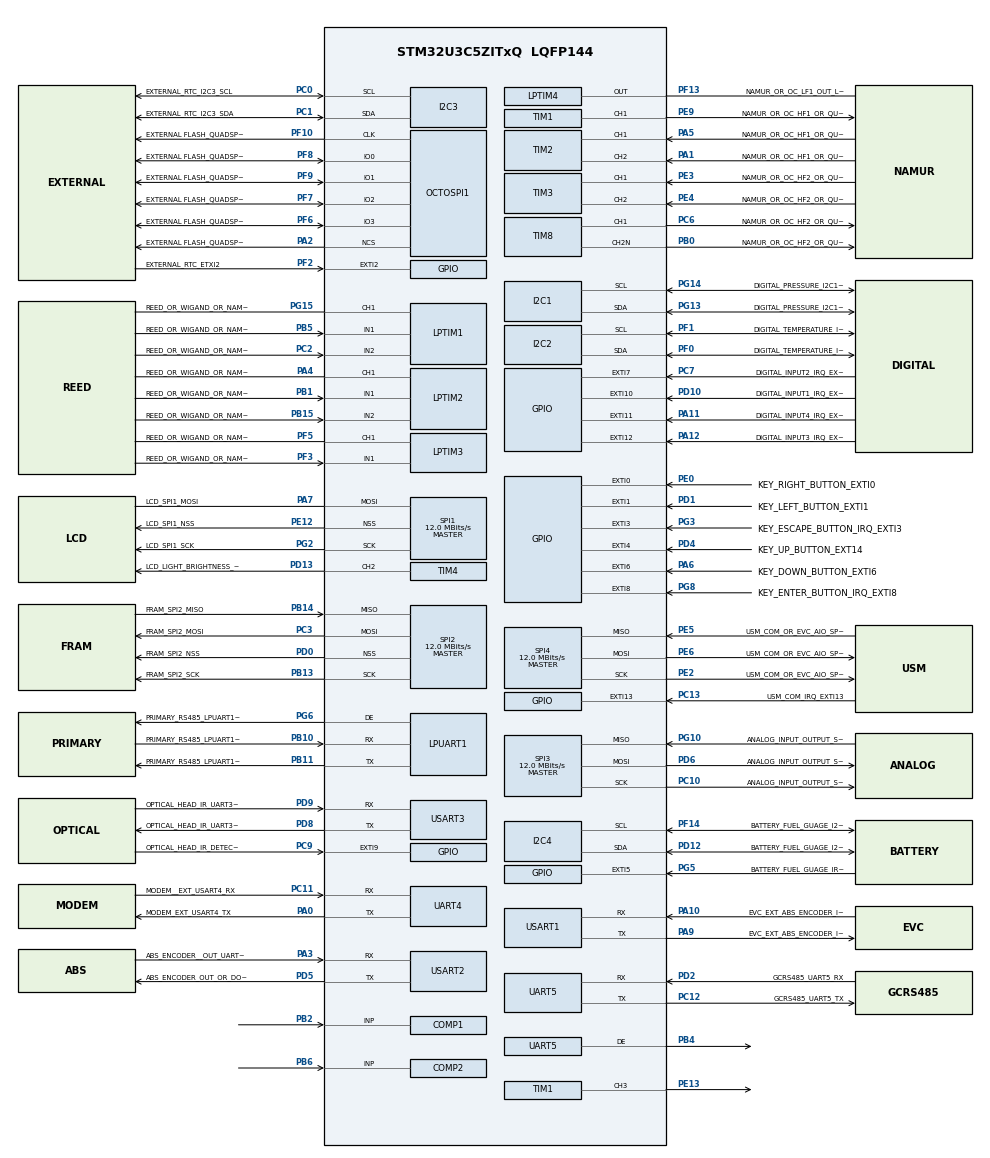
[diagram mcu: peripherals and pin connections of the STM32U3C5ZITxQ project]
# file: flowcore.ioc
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CORTEX_M33_NS.userName=CORTEX_M33
I2C1.Timing=0x00506682
I2C2.Timing=0x00506682
I2C3.Timing=0x00506682
I2C4.Timing=0x00506682
Mcu.Family=STM32U3
Mcu.Name=STM32U3C5ZITxQ
Mcu.Package=LQFP144
NVIC.PriorityGroup=NVIC_PRIORITYGROUP_4
OCTOSPI1.ClockMode=HAL_XSPI_CLOCK_MODE_3
OCTOSPI1.MemorySize=HAL_XSPI_SIZE_32MB
PA0.GPIO_Label=MODEM_EXT_USART4_TX
PA0.Mode=Asynchronous
PA0.Signal=UART4_TX
PA1.GPIO_Label=NAMUR_OR_OC_HF1_OR_QUAD1_S_INPUT_TIM2_CH2
PA1.Signal=S_TIM2_CH2
PA10.GPIO_Label=EVC_EXT_ABS_ENCODER_INPUT_UART1_RX
PA10.Mode=Asynchronous
PA10.Signal=USART1_RX
PA11.GPIO_Label=DIGITAL_INPUT4_IRQ_EXTI11
PA11.Signal=GPXTI11
PA12.GPIO_Label=DIGITAL_INPUT3_IRQ_EXTI12
PA12.Signal=GPXTI12
PA13\ (JTMS/SWDIO).Mode=JTAG_4_pins
PA13\ (JTMS/SWDIO).Signal=DEBUG_JTMS-SWDIO
PA14\ (JTCK/SWCLK).Mode=JTAG_4_pins
PA14\ (JTCK/SWCLK).Signal=DEBUG_JTCK-SWCLK
PA15\ (JTDI).Mode=JTAG_4_pins
PA15\ (JTDI).Signal=DEBUG_JTDI
PA2.GPIO_Label=EXTERNAL FLASH_QUADSPI_BK1_NCS
PA2.Mode=quad_mode
PA2.Signal=OCTOSPI1_NCS
PA3.GPIO_Label=ABS_ENCODER__OUT_UART2_RX
PA3.Mode=Asynchronous
PA3.Signal=USART2_RX
PA4.GPIO_Label=REED_OR_WIGAND_OR_NAMUR_LF3_OR_QUAD2_P_INPUT_LPTIM2_CH1
PA4.Signal=S_LPTIM2_CH1
PA5.GPIO_Label=NAMUR_OR_OC_HF1_OR_QUAD1_P_INPUT_TIM2_CH1
PA5.Signal=S_TIM2_CH1
PA6.GPIO_Label=KEY_DOWN_BUTTON_EXTI6
PA6.Signal=GPXTI6
PA7.GPIO_Label=LCD_SPI1_MOSI 
PA7.Mode=Simplex_Bidirectional_Master
PA7.Signal=SPI1_MOSI
PA9.GPIO_Label=EVC_EXT_ABS_ENCODER_INPUT_UART1_TX
PA9.Mode=Asynchronous
PA9.Signal=USART1_TX
PB0.GPIO_Label=NAMUR_OR_OC_HF2_OR_QUAD2_S_OUTPUT_TIM8_CH1N
PB0.Mode=PWM Generation2 CH2N
PB0.Signal=TIM8_CH2N
PB1.GPIO_Label=REED_OR_WIGAND_OR_NAMUR_LF3_OR_QUAD2_P_INPUT_LPTIM2_IN1
PB1.Mode=Encoder_mode_occur1
PB1.Signal=LPTIM2_IN1
PB10.GPIO_Label=PRIMARY_RS485_LPUART1_RX
PB10.Mode=Asynchronous
PB10.Signal=LPUART1_RX
PB11.GPIO_Label=PRIMARY_RS485_LPUART1_TX
PB11.Mode=Asynchronous
PB11.Signal=LPUART1_TX
PB13.GPIO_Label=FRAM_SPI2_SCK
PB13.Mode=Full_Duplex_Master
PB13.Signal=SPI2_SCK
PB14.GPIO_Label=FRAM_SPI2_MISO
PB14.Mode=Full_Duplex_Master
PB14.Signal=SPI2_MISO
PB15.GPIO_Label=REED_OR_WIGAND_OR_NAMUR_LF3_OR_QUAD2_S_INPUT_LPTIM2_IN2
PB15.Mode=Encoder_mode_occur1
PB15.Signal=LPTIM2_IN2
PB2.Mode=INP
PB2.Signal=COMP1_INP
PB3\ (JTDO/TRACESWO).Mode=JTAG_4_pins
PB3\ (JTDO/TRACESWO).Signal=DEBUG_JTDO-SWO
PB4\ (NJTRST).Mode=Hardware Flow Control (RS485)
PB4\ (NJTRST).Signal=UART5_DE
PB5.GPIO_Label=REED_OR_WIGAND_OR_NAMUR_LF1_OR_QUAD1_P_INPUT_LPTIM1_IN1
PB5.Mode=Encoder_mode_occur1
PB5.Signal=LPTIM1_IN1
PB6.Mode=INP
PB6.Signal=COMP2_INP
PC0.GPIO_Label=EXTERNAL_RTC_I2C3_SCL
PC0.Mode=I2C
PC0.Signal=I2C3_SCL
PC1.GPIO_Label=EXTERNAL_RTC_I2C3_SDA
PC1.Mode=I2C
PC1.Signal=I2C3_SDA
PC10.GPIO_Label=ANALOG_INPUT_OUTPUT_SPI3_SCK
PC10.Mode=Full_Duplex_Master
PC10.Signal=SPI3_SCK
PC11.GPIO_Label=MODEM__EXT_USART4_RX
PC11.Mode=Asynchronous
PC11.Signal=UART4_RX
PC12.GPIO_Label=GCRS485_UART5_TX
PC12.Mode=Asynchronous
PC12.Signal=UART5_TX
PC13.GPIO_Label=USM_COM_IRQ_EXTI13
PC13.Signal=GPXTI13
PC14-OSC32_IN\ (PC14).GPIO_Label=RCC_OSCC32_IN
PC14-OSC32_IN\ (PC14).Mode=LSE-External-Oscillator
PC14-OSC32_IN\ (PC14).Signal=RCC_OSC32_IN
PC15-OSC32_OUT\ (PC15).GPIO_Label=RCC_OSCC32_OUT
PC15-OSC32_OUT\ (PC15).Mode=LSE-External-Oscillator
PC15-OSC32_OUT\ (PC15).Signal=RCC_OSC32_OUT
PC2.GPIO_Label=REED_OR_WIGAND_OR_NAMUR_LF2_OR_QUAD1_S_INPUT_LPTIM1_IN2
PC2.Mode=Encoder_mode_occur1
PC2.Signal=LPTIM1_IN2
PC3.GPIO_Label=FRAM_SPI2_MOSI
PC3.Mode=Full_Duplex_Master
PC3.Signal=SPI2_MOSI
PC6.GPIO_Label=NAMUR_OR_OC_HF2_OR_QUAD2_P_OUTPUT_OR_DO2_TIM8_CH1
PC6.Signal=S_TIM8_CH1
PC7.GPIO_Label=DIGITAL_INPUT2_IRQ_EXTI7
PC7.Signal=GPXTI7
PC9.GPIO_Label=OPTICAL_HEAD_IR_DETECT_IRQ_EXTI9
PC9.Signal=GPXTI9
PD0.GPIO_Label=FRAM_SPI2_NSS
PD0.Mode=NSS_Signal_Hard_Output
PD0.Signal=SPI2_NSS
PD1.GPIO_Label=KEY_LEFT_BUTTON_EXTI1
PD1.Signal=GPXTI1
PD10.GPIO_Label=DIGITAL_INPUT1_IRQ_EXTI10
PD10.Signal=GPXTI10
PD12.GPIO_Label=BATTERY_FUEL_GUAGE_I2C4_SDA
PD12.Mode=I2C
PD12.Signal=I2C4_SDA
PD13.GPIO_Label=LCD_LIGHT_BRIGHTNESS_CONTROLL_PWM_TIM4_CH2
PD13.Signal=S_TIM4_CH2
PD2.GPIO_Label=GCRS485_UART5_RX
PD2.Mode=Asynchronous
PD2.Signal=UART5_RX
PD4.GPIO_Label=KEY_UP_BUTTON_EXT14
PD4.Signal=GPXTI4
PD5.GPIO_Label=ABS_ENCODER_OUT_OR_DO3_UART2_TX
PD5.Mode=Asynchronous
PD5.Signal=USART2_TX
PD6.GPIO_Label=ANALOG_INPUT_OUTPUT_SPI3_MOSI
PD6.Mode=Full_Duplex_Master
PD6.Signal=SPI3_MOSI
PD8.GPIO_Label=OPTICAL_HEAD_IR_UART3_TX
PD8.Mode=Asynchronous
PD8.Signal=USART3_TX
PD9.GPIO_Label=OPTICAL_HEAD_IR_UART3_RX_OR_IRQ_EXTI9
PD9.Mode=Asynchronous
PD9.Signal=USART3_RX
PE0.GPIO_Label=KEY_RIGHT_BUTTON_EXTI0
PE0.Signal=GPXTI0
PE12.GPIO_Label=LCD_SPI1_NSS
PE12.Mode=NSS_Signal_Hard_Output
PE12.Signal=SPI1_NSS
PE13.Signal=S_TIM1_CH3
PE2.GPIO_Label=USM_COM_OR_EVC_AIO_SPI4_SCK
PE2.Mode=Full_Duplex_Master
PE2.Signal=SPI4_SCK
PE3.GPIO_Label=NAMUR_OR_OC_HF2_OR_QUAD2_P_INPUT_TIM3_CH1
PE3.Signal=S_TIM3_CH1
PE4.GPIO_Label=NAMUR_OR_OC_HF2_OR_QUAD2_S_INPUT_TIM3_CH2
PE4.Signal=S_TIM3_CH2
PE5.GPIO_Label=USM_COM_OR_EVC_AIO_SPI4_MISO
PE5.Mode=Full_Duplex_Master
PE5.Signal=SPI4_MISO
PE6.GPIO_Label=USM_COM_OR_EVC_AIO_SPI4_MOSI
PE6.Mode=Full_Duplex_Master
PE6.Signal=SPI4_MOSI
PE9.GPIO_Label=NAMUR_OR_OC_HF1_OR_QUAD1_P_OUTPUT_OR_DO1_TIM1_CH1
PE9.Signal=S_TIM1_CH1
PF0.GPIO_Label=DIGITAL_TEMPERATURE_I2C2_SDA
PF0.Mode=I2C
PF0.Signal=I2C2_SDA
PF1.GPIO_Label=DIGITAL_TEMPERATURE_I2C2_SCL
PF1.Mode=I2C
PF1.Signal=I2C2_SCL
PF10.GPIO_Label=EXTERNAL FLASH_QUADSPI_CLK
PF10.Mode=quad_mode
PF10.Signal=OCTOSPI1_CLK
PF13.GPIO_Label=NAMUR_OR_OC_LF1_OUT_LPTIM4_OUT
PF13.Mode=WaveformGeneration
PF13.Signal=LPTIM4_OUT
PF14.GPIO_Label=BATTERY_FUEL_GUAGE_I2C4_SCL
PF14.Mode=I2C
PF14.Signal=I2C4_SCL
PF2.GPIO_Label=EXTERNAL_RTC_ETXI2
PF2.Signal=GPXTI2
PF3.GPIO_Label=REED_OR_WIGAND_OR_NAMUR_LF2_OR_QUAD1_S_INPUT_LPTIM3_IN1
PF3.Mode=Counts_external_clock_with_synchro_01_occur1
PF3.Signal=LPTIM3_IN1
PF5.GPIO_Label=REED_OR_WIGAND_OR_NAMUR_LF2_OR_QUAD1_S_INPUT_LPTIM3_CH1
PF5.Signal=S_LPTIM3_CH1
PF6.GPIO_Label=EXTERNAL FLASH_QUADSPI_BK1_IO3
PF6.Mode=OCTOSPI1_IO[3\:0]
PF6.Signal=OCTOSPI1_IO3
PF7.GPIO_Label=EXTERNAL FLASH_QUADSPI_BK1_IO2
PF7.Mode=OCTOSPI1_IO[3\:0]
PF7.Signal=OCTOSPI1_IO2
PF8.GPIO_Label=EXTERNAL FLASH_QUADSPI_BK1_IO0
PF8.Mode=OCTOSPI1_IO[3\:0]
PF8.Signal=OCTOSPI1_IO0
PF9.GPIO_Label=EXTERNAL FLASH_QUADSPI_BK1_IO1
PF9.Mode=OCTOSPI1_IO[3\:0]
PF9.Signal=OCTOSPI1_IO1
PG10.GPIO_Label=ANALOG_INPUT_OUTPUT_SPI3_MISO
PG10.Mode=Full_Duplex_Master
PG10.Signal=SPI3_MISO
PG13.GPIO_Label=DIGITAL_PRESSURE_I2C1_SDA
PG13.Mode=I2C
PG13.Signal=I2C1_SDA
PG14.GPIO_Label=DIGITAL_PRESSURE_I2C1_SCL
PG14.Mode=I2C
PG14.Signal=I2C1_SCL
PG15.GPIO_Label=REED_OR_WIGAND_OR_NAMUR_LF1_OR_QUAD1_P_INPUT_LPTIM1_CH1
PG15.Signal=S_LPTIM1_CH1
PG2.GPIO_Label=LCD_SPI1_SCK
PG2.Mode=Simplex_Bidirectional_Master
PG2.Signal=SPI1_SCK
PG3.GPIO_Label=KEY_ESCAPE_BUTTON_IRQ_EXTI3
PG3.Signal=GPXTI3
PG5.GPIO_Label=BATTERY_FUEL_GUAGE_IRQ_ETXI15
PG5.Signal=GPXTI5
PG6.GPIO_Label=PRIMARY_RS485_LPUART1_DE
PG6.Mode=Hardware Flow Control (RS485)
PG6.Signal=LPUART1_DE
PG8.GPIO_Label=KEY_ENTER_BUTTON_IRQ_EXTI8
PG8.Signal=GPXTI8
PH0-OSC_IN\ (PH0).Mode=HSE-External-Oscillator
PH0-OSC_IN\ (PH0).Signal=RCC_OSC_IN
PH1-OSC_OUT\ (PH1).Mode=HSE-External-Oscillator
PH1-OSC_OUT\ (PH1).Signal=RCC_OSC_OUT
ProjectManager.HeapSize=0x200
ProjectManager.StackSize=0x400
ProjectManager.TargetToolchain=STM32CubeIDE
RCC.ADCFreq_Value=24000000
RCC.AHBFreq_Value=24000000
RCC.APB1Freq_Value=24000000
RCC.APB1TimFreq_Value=24000000
RCC.APB2Freq_Value=24000000
RCC.APB2TimFreq_Value=24000000
RCC.APB3Freq_Value=24000000
RCC.CortexFreq_Value=3000000
RCC.HCLKFreq_Value=24000000
RCC.HSE_VALUE=16000000
RCC.HSI48_VALUE=48000000
RCC.HSI_VALUE=16000000
RCC.LPTIM1CLockSelection=RCC_LPTIM1CLKSOURCE_LSE
RCC.LPTIM2CLockSelection=RCC_LPTIM2CLKSOURCE_LSE
RCC.LPTIM3CLockSelection=RCC_LPTIM34CLKSOURCE_LSE
RCC.LSIDIV_VALUE=32000
RCC.MSIKSource=RCC_MSI_RC1
RCC.MSISDIV=RCC_MSI_DIV1
RCC.MSISSource=RCC_MSI_RC1
RCC.RTCClockSelection=RCC_RTCCLKSOURCE_LSE
RCC.SYSCLKFreq_VALUE=24000000
RCC.USBFreq_Value=24000000
SH.S_LPTIM1_CH1.0=LPTIM1_CH1,InputIO_CH1
SH.S_LPTIM2_CH1.0=LPTIM2_CH1,InputIO_CH1
SH.S_LPTIM3_CH1.0=LPTIM3_CH1,InputIO_CH1
SH.S_TIM1_CH1.0=TIM1_CH1,PWM Generation1 CH1
SH.S_TIM1_CH3.0=TIM1_CH3,PWM Generation3 CH3
SH.S_TIM2_CH1.0=TIM2_CH1,Encoder_Interface
SH.S_TIM2_CH2.0=TIM2_CH2,Encoder_Interface
SH.S_TIM3_CH1.0=TIM3_CH1,Encoder_Interface
SH.S_TIM3_CH2.0=TIM3_CH2,Encoder_Interface
SH.S_TIM4_CH2.0=TIM4_CH2,PWM Generation2 CH2
SH.S_TIM8_CH1.0=TIM8_CH1,PWM Generation1 CH1
SPI1.CalculateBaudRate=12.0 MBits/s
SPI1.DataSize=SPI_DATASIZE_8BIT
SPI1.Direction=SPI_DIRECTION_1LINE
SPI1.Mode=SPI_MODE_MASTER
SPI1.VirtualNSS=VM_NSSHARD
SPI1.VirtualType=VM_MASTER
SPI2.CalculateBaudRate=12.0 MBits/s
SPI2.Direction=SPI_DIRECTION_2LINES
SPI2.Mode=SPI_MODE_MASTER
SPI2.VirtualNSS=VM_NSSHARD
SPI2.VirtualType=VM_MASTER
SPI3.CalculateBaudRate=12.0 MBits/s
SPI3.Direction=SPI_DIRECTION_2LINES
SPI3.Mode=SPI_MODE_MASTER
SPI3.NSSPMode=SPI_NSS_PULSE_ENABLE
SPI3.VirtualType=VM_MASTER
SPI4.CalculateBaudRate=12.0 MBits/s
SPI4.Direction=SPI_DIRECTION_2LINES
SPI4.Mode=SPI_MODE_MASTER
SPI4.VirtualType=VM_MASTER
TIM1.AutoReloadPreload=TIM_AUTORELOAD_PRELOAD_DISABLE
TIM1.Channel-Output\ Compare2\ No\ Output=TIM_CHANNEL_2
TIM1.Channel-Output\ Compare4\ No\ Output=TIM_CHANNEL_4
TIM1.Channel-PWM\ Generation1\ CH1=TIM_CHANNEL_1
TIM1.Channel-PWM\ Generation3\ CH3=TIM_CHANNEL_3
TIM1.CounterMode=TIM_COUNTERMODE_CENTERALIGNED3
TIM1.OC1Preload_PWM=DISABLE
TIM1.OC3Preload_PWM=DISABLE
TIM1.OCMode_PWM-PWM\ Generation1\ CH1=TIM_OCMODE_ASSYMETRIC_PWM1
TIM1.OCMode_PWM-PWM\ Generation3\ CH3=TIM_OCMODE_ASSYMETRIC_PWM2
TIM1.PeriodNoDither=500
TIM1.Prescaler=23
TIM1.PulseNoDither_1=125
TIM1.PulseNoDither_2=375
TIM1.PulseNoDither_3=375
TIM1.PulseNoDither_4=25
TIM1.RepetitionCounter=1999
TIM4.Channel-PWM\ Generation2\ CH2=TIM_CHANNEL_2
TIM8.Channel-PWM\ Generation1\ CH1=TIM_CHANNEL_1
TIM8.Channel-PWM\ Generation2\ CH2N=TIM_CHANNEL_2
USART1.VirtualMode-Asynchronous=VM_ASYNC
USART2.VirtualMode-Asynchronous=VM_ASYNC
USART3.VirtualMode-Asynchronous=VM_ASYNC
VP_COMP1_VS_VREFINT.Mode=VREFINT
VP_COMP2_VS_VREFINT.Mode=VREFINT
VP_CORTEX_M33_NS_VS_Hclk.Mode=Hclk_Mode
VP_ICACHE_VS_ICACHE.Mode=DirectMappedCache
VP_LPTIM1_VS_CH1.Mode=Channel_1_Active
VP_LPTIM2_VS_CH1.Mode=Channel_1_Active
VP_LPTIM3_VS_CH1.Mode=Channel_1_Active
VP_LPTIM4_VS_LPTIM_counterModeInternalClock.Mode=Counts__internal_clock_event_00
VP_PWR_VS_DBSignals.Mode=DisableDeadBatterySignals
VP_PWR_VS_SECSignals.Mode=Security/Privilege
VP_RTC_VS_RTC_Activate.Mode=RTC_Enabled
VP_TIM1_VS_ClockSourceINT.Mode=Internal
VP_TIM1_VS_no_output2.Mode=Output Compare2 No Output
VP_TIM1_VS_no_output4.Mode=Output Compare4 No Output
board=custom

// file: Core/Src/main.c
/* USER CODE BEGIN Header */
/**
  ******************************************************************************
  * @file           : main.c
  * @brief          : Main program body
  ******************************************************************************
  * @attention
  *
  * Copyright (c) 2026 STMicroelectronics.
  * All rights reserved.
  *
  * This software is licensed under terms that can be found in the LICENSE file
  * in the root directory of this software component.
  * If no LICENSE file comes with this software, it is provided AS-IS.
  *
  ******************************************************************************
  */
/* USER CODE END Header */
#include "main.h"

COMP_HandleTypeDef hcomp1;
COMP_HandleTypeDef hcomp2;

I2C_HandleTypeDef hi2c1;
I2C_HandleTypeDef hi2c2;
I2C_HandleTypeDef hi2c3;
I2C_HandleTypeDef hi2c4;

LPTIM_HandleTypeDef hlptim1;
LPTIM_HandleTypeDef hlptim2;
LPTIM_HandleTypeDef hlptim3;
LPTIM_HandleTypeDef hlptim4;

UART_HandleTypeDef hlpuart1;
UART_HandleTypeDef huart4;
UART_HandleTypeDef huart5;
UART_HandleTypeDef huart1;
UART_HandleTypeDef huart2;
UART_HandleTypeDef huart3;

XSPI_HandleTypeDef hxspi1;

RTC_HandleTypeDef hrtc;

SPI_HandleTypeDef hspi1;
SPI_HandleTypeDef hspi2;
SPI_HandleTypeDef hspi3;
SPI_HandleTypeDef hspi4;

TIM_HandleTypeDef htim1;
TIM_HandleTypeDef htim2;
TIM_HandleTypeDef htim3;
TIM_HandleTypeDef htim4;
TIM_HandleTypeDef htim8;

void SystemClock_Config(void);
static void MX_GPIO_Init(void);
static void MX_I2C1_Init(void);
static void MX_I2C2_Init(void);
static void MX_I2C3_Init(void);
static void MX_LPUART1_UART_Init(void);
static void MX_UART4_Init(void);
static void MX_UART5_Init(void);
static void MX_USART1_UART_Init(void);
static void MX_USART2_UART_Init(void);
static void MX_USART3_UART_Init(void);
static void MX_OCTOSPI1_Init(void);
static void MX_SPI1_Init(void);
static void MX_SPI2_Init(void);
static void MX_SPI3_Init(void);
static void MX_SPI4_Init(void);
static void MX_LPTIM1_Init(void);
static void MX_LPTIM3_Init(void);
static void MX_I2C4_Init(void);
static void MX_ICACHE_Init(void);
static void MX_RTC_Init(void);
static void MX_COMP1_Init(void);
static void MX_COMP2_Init(void);
static void MX_LPTIM2_Init(void);
static void MX_LPTIM4_Init(void);
static void MX_TIM1_Init(void);
static void MX_TIM2_Init(void);
static void MX_TIM3_Init(void);
static void MX_TIM8_Init(void);
static void MX_TIM4_Init(void);

int main(void)
{

  /* MCU Configuration--------------------------------------------------------*/

  /* Reset of all peripherals, Initializes the Flash interface and the Systick. */
  HAL_Init();

  /* Configure the system clock */
  SystemClock_Config();

  /* Initialize all configured peripherals */
  MX_GPIO_Init();
  MX_I2C1_Init();
  MX_I2C2_Init();
  MX_I2C3_Init();
  MX_LPUART1_UART_Init();
  MX_UART4_Init();
  MX_UART5_Init();
  MX_USART1_UART_Init();
  MX_USART2_UART_Init();
  MX_USART3_UART_Init();
  MX_OCTOSPI1_Init();
  MX_SPI1_Init();
  MX_SPI2_Init();
  MX_SPI3_Init();
  MX_SPI4_Init();
  MX_LPTIM1_Init();
  MX_LPTIM3_Init();
  MX_I2C4_Init();
  MX_ICACHE_Init();
  MX_RTC_Init();
  MX_COMP1_Init();
  MX_COMP2_Init();
  MX_LPTIM2_Init();
  MX_LPTIM4_Init();
  MX_TIM1_Init();
  MX_TIM2_Init();
  MX_TIM3_Init();
  MX_TIM8_Init();
  MX_TIM4_Init();
  /* USER CODE BEGIN 2 */

  TIM_OC_InitTypeDef phaseConfig = {0};

  const uint32_t channels[4] = {
      TIM_CHANNEL_1, TIM_CHANNEL_2,
      TIM_CHANNEL_3, TIM_CHANNEL_4
  };

  const uint32_t compareValues[4] = {
      125, 375, 375, 125
  };

  phaseConfig.OCMode = TIM_OCMODE_ASYMMETRIC_PWM2;
  phaseConfig.OCPolarity = TIM_OCPOLARITY_HIGH;
  phaseConfig.OCNPolarity = TIM_OCNPOLARITY_HIGH;
  phaseConfig.OCFastMode = TIM_OCFAST_DISABLE;
  phaseConfig.OCIdleState = TIM_OCIDLESTATE_RESET;
  phaseConfig.OCNIdleState = TIM_OCNIDLESTATE_RESET;

  for (uint32_t i = 0; i < 4; i++)
  {
      phaseConfig.Pulse = compareValues[i];

      if (HAL_TIM_PWM_ConfigChannel(
              &htim1, &phaseConfig, channels[i]) != HAL_OK)
      {
          Error_Handler();
      }
  }

  /* Stop after 1000 complete up/down periods. */
  SET_BIT(htim1.Instance->CR1, TIM_CR1_OPM);

  /* Load all timing values before starting. */
  htim1.Instance->EGR = TIM_EGR_UG;
  __HAL_TIM_CLEAR_FLAG(&htim1, TIM_FLAG_UPDATE);

  /* Enable A and B together, then start their shared counter. */
  SET_BIT(htim1.Instance->CCER,
          TIM_CCER_CC1E | TIM_CCER_CC3E);

  __HAL_TIM_MOE_ENABLE(&htim1);
  __HAL_TIM_ENABLE(&htim1);

  //////////////////////////////////////////////////////////

  // SET_BIT(htim1.Instance->CR1, TIM_CR1_OPM);

  // htim1.Instance->EGR = TIM_EGR_UG;
  // __HAL_TIM_CLEAR_FLAG(&htim1, TIM_FLAG_UPDATE);

  // if (HAL_TIM_PWM_Start(&htim1, TIM_CHANNEL_1) != HAL_OK)
  // {
  //     Error_Handler();
  // }
  /* USER CODE END 2 */

  /* Infinite loop */
  while (1)
  {

    /* USER CODE BEGIN 3 */
    while ((htim1.Instance->CR1 & TIM_CR1_CEN) != 0U)
    {
    }

    /* Keep the output LOW for 10 seconds. */
    HAL_Delay(10000);

    /* Reload the counter for the next 500-pulse burst. */
    htim1.Instance->EGR = TIM_EGR_UG;
    __HAL_TIM_CLEAR_FLAG(&htim1, TIM_FLAG_UPDATE);

    /* Restart the counter; the PWM channel remains enabled. */
    __HAL_TIM_ENABLE(&htim1);
  }

  /* USER CODE END 3 */
}

void SystemClock_Config(void)
{
  RCC_OscInitTypeDef RCC_OscInitStruct = {0};
  RCC_ClkInitTypeDef RCC_ClkInitStruct = {0};

  /** Configure the System Power Supply
  */
  if (HAL_PWREx_ConfigSupply(PWR_SMPS_SUPPLY) != HAL_OK)
  {
    Error_Handler();
  }

  /** Configure the main internal regulator output voltage
  */
  if (HAL_PWREx_ControlVoltageScaling(PWR_REGULATOR_VOLTAGE_SCALE2) != HAL_OK)
  {
    Error_Handler();
  }

  /** Configure LSE Drive Capability
  */
  HAL_PWR_EnableBkUpAccess();
  __HAL_RCC_LSEDRIVE_CONFIG(RCC_LSEDRIVE_LOW);

  /** Initializes the CPU, AHB and APB buses clocks
  */
  RCC_OscInitStruct.OscillatorType = RCC_OSCILLATORTYPE_LSE|RCC_OSCILLATORTYPE_MSIS;
  RCC_OscInitStruct.LSEState = RCC_LSE_ON;
  RCC_OscInitStruct.MSISState = RCC_MSI_ON;
  RCC_OscInitStruct.MSISSource = RCC_MSI_RC1;
  RCC_OscInitStruct.MSISDiv = RCC_MSI_DIV1;
  if (HAL_RCC_OscConfig(&RCC_OscInitStruct) != HAL_OK)
  {
    Error_Handler();
  }

  /** Initializes the CPU, AHB and APB buses clocks
  */
  RCC_ClkInitStruct.ClockType = RCC_CLOCKTYPE_HCLK|RCC_CLOCKTYPE_SYSCLK
                              |RCC_CLOCKTYPE_PCLK1|RCC_CLOCKTYPE_PCLK2
                              |RCC_CLOCKTYPE_PCLK3;
  RCC_ClkInitStruct.SYSCLKSource = RCC_SYSCLKSOURCE_MSIS;
  RCC_ClkInitStruct.AHBCLKDivider = RCC_SYSCLK_DIV1;
  RCC_ClkInitStruct.APB1CLKDivider = RCC_HCLK_DIV1;
  RCC_ClkInitStruct.APB2CLKDivider = RCC_HCLK_DIV1;
  RCC_ClkInitStruct.APB3CLKDivider = RCC_HCLK_DIV1;

  if (HAL_RCC_ClockConfig(&RCC_ClkInitStruct, FLASH_LATENCY_1) != HAL_OK)
  {
    Error_Handler();
  }
}

static void MX_COMP1_Init(void)
{

  hcomp1.Instance = COMP1;
  hcomp1.Init.InputPlus = COMP_INPUT_PLUS_IO2;
  hcomp1.Init.InputMinus = COMP_INPUT_MINUS_VREFINT;
  hcomp1.Init.OutputPol = COMP_OUTPUTPOL_NONINVERTED;
  hcomp1.Init.WindowOutput = COMP_WINDOWOUTPUT_EACH_COMP;
  hcomp1.Init.Hysteresis = COMP_HYSTERESIS_NONE;
  hcomp1.Init.BlankingSrce = COMP_BLANKINGSRC_NONE;
  hcomp1.Init.Mode = COMP_POWERMODE_HIGHSPEED;
  hcomp1.Init.WindowMode = COMP_WINDOWMODE_DISABLE;
  hcomp1.Init.TriggerMode = COMP_TRIGGERMODE_NONE;
  if (HAL_COMP_Init(&hcomp1) != HAL_OK)
  {
    Error_Handler();
  }

}

static void MX_COMP2_Init(void)
{

  hcomp2.Instance = COMP2;
  hcomp2.Init.InputPlus = COMP_INPUT_PLUS_IO2;
  hcomp2.Init.InputMinus = COMP_INPUT_MINUS_VREFINT;
  hcomp2.Init.OutputPol = COMP_OUTPUTPOL_NONINVERTED;
  hcomp2.Init.WindowOutput = COMP_WINDOWOUTPUT_EACH_COMP;
  hcomp2.Init.Hysteresis = COMP_HYSTERESIS_NONE;
  hcomp2.Init.BlankingSrce = COMP_BLANKINGSRC_NONE;
  hcomp2.Init.Mode = COMP_POWERMODE_HIGHSPEED;
  hcomp2.Init.WindowMode = COMP_WINDOWMODE_DISABLE;
  hcomp2.Init.TriggerMode = COMP_TRIGGERMODE_NONE;
  if (HAL_COMP_Init(&hcomp2) != HAL_OK)
  {
    Error_Handler();
  }

}

static void MX_I2C1_Init(void)
{

  hi2c1.Instance = I2C1;
  hi2c1.Init.Timing = 0x00506682;
  hi2c1.Init.OwnAddress1 = 0;
  hi2c1.Init.AddressingMode = I2C_ADDRESSINGMODE_7BIT;
  hi2c1.Init.DualAddressMode = I2C_DUALADDRESS_DISABLE;
  hi2c1.Init.OwnAddress2 = 0;
  hi2c1.Init.OwnAddress2Masks = I2C_OA2_NOMASK;
  hi2c1.Init.GeneralCallMode = I2C_GENERALCALL_DISABLE;
  hi2c1.Init.NoStretchMode = I2C_NOSTRETCH_DISABLE;
  if (HAL_I2C_Init(&hi2c1) != HAL_OK)
  {
    Error_Handler();
  }

  /** Configure Analogue filter
  */
  if (HAL_I2CEx_ConfigAnalogFilter(&hi2c1, I2C_ANALOGFILTER_ENABLE) != HAL_OK)
  {
    Error_Handler();
  }

  /** Configure Digital filter
  */
  if (HAL_I2CEx_ConfigDigitalFilter(&hi2c1, 0) != HAL_OK)
  {
    Error_Handler();
  }

}

static void MX_I2C2_Init(void)
{

  hi2c2.Instance = I2C2;
  hi2c2.Init.Timing = 0x00506682;
  hi2c2.Init.OwnAddress1 = 0;
  hi2c2.Init.AddressingMode = I2C_ADDRESSINGMODE_7BIT;
  hi2c2.Init.DualAddressMode = I2C_DUALADDRESS_DISABLE;
  hi2c2.Init.OwnAddress2 = 0;
  hi2c2.Init.OwnAddress2Masks = I2C_OA2_NOMASK;
  hi2c2.Init.GeneralCallMode = I2C_GENERALCALL_DISABLE;
  hi2c2.Init.NoStretchMode = I2C_NOSTRETCH_DISABLE;
  if (HAL_I2C_Init(&hi2c2) != HAL_OK)
  {
    Error_Handler();
  }

  /** Configure Analogue filter
  */
  if (HAL_I2CEx_ConfigAnalogFilter(&hi2c2, I2C_ANALOGFILTER_ENABLE) != HAL_OK)
  {
    Error_Handler();
  }

  /** Configure Digital filter
  */
  if (HAL_I2CEx_ConfigDigitalFilter(&hi2c2, 0) != HAL_OK)
  {
    Error_Handler();
  }

}

static void MX_I2C3_Init(void)
{

  hi2c3.Instance = I2C3;
  hi2c3.Init.Timing = 0x00506682;
  hi2c3.Init.OwnAddress1 = 0;
  hi2c3.Init.AddressingMode = I2C_ADDRESSINGMODE_7BIT;
  hi2c3.Init.DualAddressMode = I2C_DUALADDRESS_DISABLE;
  hi2c3.Init.OwnAddress2 = 0;
  hi2c3.Init.OwnAddress2Masks = I2C_OA2_NOMASK;
  hi2c3.Init.GeneralCallMode = I2C_GENERALCALL_DISABLE;
  hi2c3.Init.NoStretchMode = I2C_NOSTRETCH_DISABLE;
  if (HAL_I2C_Init(&hi2c3) != HAL_OK)
  {
    Error_Handler();
  }

  /** Configure Analogue filter
  */
  if (HAL_I2CEx_ConfigAnalogFilter(&hi2c3, I2C_ANALOGFILTER_ENABLE) != HAL_OK)
  {
    Error_Handler();
  }

  /** Configure Digital filter
  */
  if (HAL_I2CEx_ConfigDigitalFilter(&hi2c3, 0) != HAL_OK)
  {
    Error_Handler();
  }

}

static void MX_I2C4_Init(void)
{

  hi2c4.Instance = I2C4;
  hi2c4.Init.Timing = 0x00506682;
  hi2c4.Init.OwnAddress1 = 0;
  hi2c4.Init.AddressingMode = I2C_ADDRESSINGMODE_7BIT;
  hi2c4.Init.DualAddressMode = I2C_DUALADDRESS_DISABLE;
  hi2c4.Init.OwnAddress2 = 0;
  hi2c4.Init.OwnAddress2Masks = I2C_OA2_NOMASK;
  hi2c4.Init.GeneralCallMode = I2C_GENERALCALL_DISABLE;
  hi2c4.Init.NoStretchMode = I2C_NOSTRETCH_DISABLE;
  if (HAL_I2C_Init(&hi2c4) != HAL_OK)
  {
    Error_Handler();
  }

  /** Configure Analogue filter
  */
  if (HAL_I2CEx_ConfigAnalogFilter(&hi2c4, I2C_ANALOGFILTER_ENABLE) != HAL_OK)
  {
    Error_Handler();
  }

  /** Configure Digital filter
  */
  if (HAL_I2CEx_ConfigDigitalFilter(&hi2c4, 0) != HAL_OK)
  {
    Error_Handler();
  }

}

static void MX_ICACHE_Init(void)
{

  /** Enable instruction cache in 1-way (direct mapped cache)
  */
  if (HAL_ICACHE_ConfigAssociativityMode(ICACHE_1WAY) != HAL_OK)
  {
    Error_Handler();
  }
  if (HAL_ICACHE_Enable() != HAL_OK)
  {
    Error_Handler();
  }

}

static void MX_LPTIM1_Init(void)
{

  LPTIM_IC_ConfigTypeDef sConfig = {0};

  hlptim1.Instance = LPTIM1;
  hlptim1.Init.Clock.Source = LPTIM_CLOCKSOURCE_APBCLOCK_LPOSC;
  hlptim1.Init.Clock.Prescaler = LPTIM_PRESCALER_DIV1;
  hlptim1.Init.UltraLowPowerClock.Polarity = LPTIM_CLOCKPOLARITY_RISING;
  hlptim1.Init.UltraLowPowerClock.SampleTime = LPTIM_CLOCKSAMPLETIME_DIRECTTRANSITION;
  hlptim1.Init.Trigger.Source = LPTIM_TRIGSOURCE_SOFTWARE;
  hlptim1.Init.Period = 65535;
  hlptim1.Init.UpdateMode = LPTIM_UPDATE_IMMEDIATE;
  hlptim1.Init.CounterSource = LPTIM_COUNTERSOURCE_EXTERNAL;
  hlptim1.Init.Input1Source = LPTIM_INPUT1SOURCE_GPIO;
  hlptim1.Init.RepetitionCounter = 0;
  if (HAL_LPTIM_Init(&hlptim1) != HAL_OK)
  {
    Error_Handler();
  }
  sConfig.ICInputSource = LPTIM_IC1SOURCE_GPIO;
  sConfig.ICPrescaler = LPTIM_ICPSC_DIV1;
  sConfig.ICPolarity = LPTIM_ICPOLARITY_RISING;
  sConfig.ICFilter = LPTIM_ICFLT_CLOCK_DIV1;
  if (HAL_LPTIM_IC_ConfigChannel(&hlptim1, &sConfig, LPTIM_CHANNEL_1) != HAL_OK)
  {
    Error_Handler();
  }

}

static void MX_LPTIM2_Init(void)
{

  LPTIM_IC_ConfigTypeDef sConfig = {0};

  hlptim2.Instance = LPTIM2;
  hlptim2.Init.Clock.Source = LPTIM_CLOCKSOURCE_APBCLOCK_LPOSC;
  hlptim2.Init.Clock.Prescaler = LPTIM_PRESCALER_DIV1;
  hlptim2.Init.UltraLowPowerClock.Polarity = LPTIM_CLOCKPOLARITY_RISING;
  hlptim2.Init.UltraLowPowerClock.SampleTime = LPTIM_CLOCKSAMPLETIME_DIRECTTRANSITION;
  hlptim2.Init.Trigger.Source = LPTIM_TRIGSOURCE_SOFTWARE;
  hlptim2.Init.Period = 65535;
  hlptim2.Init.UpdateMode = LPTIM_UPDATE_IMMEDIATE;
  hlptim2.Init.CounterSource = LPTIM_COUNTERSOURCE_EXTERNAL;
  hlptim2.Init.Input1Source = LPTIM_INPUT1SOURCE_GPIO;
  hlptim2.Init.RepetitionCounter = 0;
  if (HAL_LPTIM_Init(&hlptim2) != HAL_OK)
  {
    Error_Handler();
  }
  sConfig.ICInputSource = LPTIM_IC1SOURCE_GPIO;
  sConfig.ICPrescaler = LPTIM_ICPSC_DIV1;
  sConfig.ICPolarity = LPTIM_ICPOLARITY_RISING;
  sConfig.ICFilter = LPTIM_ICFLT_CLOCK_DIV1;
  if (HAL_LPTIM_IC_ConfigChannel(&hlptim2, &sConfig, LPTIM_CHANNEL_1) != HAL_OK)
  {
    Error_Handler();
  }

}

static void MX_LPTIM3_Init(void)
{

  LPTIM_IC_ConfigTypeDef sConfig = {0};

  hlptim3.Instance = LPTIM3;
  hlptim3.Init.Clock.Source = LPTIM_CLOCKSOURCE_APBCLOCK_LPOSC;
  hlptim3.Init.Clock.Prescaler = LPTIM_PRESCALER_DIV1;
  hlptim3.Init.UltraLowPowerClock.Polarity = LPTIM_CLOCKPOLARITY_RISING;
  hlptim3.Init.UltraLowPowerClock.SampleTime = LPTIM_CLOCKSAMPLETIME_DIRECTTRANSITION;
  hlptim3.Init.Trigger.Source = LPTIM_TRIGSOURCE_SOFTWARE;
  hlptim3.Init.Period = 65535;
  hlptim3.Init.UpdateMode = LPTIM_UPDATE_IMMEDIATE;
  hlptim3.Init.CounterSource = LPTIM_COUNTERSOURCE_EXTERNAL;
  hlptim3.Init.Input1Source = LPTIM_INPUT1SOURCE_GPIO;
  hlptim3.Init.RepetitionCounter = 0;
  if (HAL_LPTIM_Init(&hlptim3) != HAL_OK)
  {
    Error_Handler();
  }
  sConfig.ICInputSource = LPTIM_IC1SOURCE_GPIO;
  sConfig.ICPrescaler = LPTIM_ICPSC_DIV1;
  sConfig.ICPolarity = LPTIM_ICPOLARITY_RISING;
  sConfig.ICFilter = LPTIM_ICFLT_CLOCK_DIV1;
  if (HAL_LPTIM_IC_ConfigChannel(&hlptim3, &sConfig, LPTIM_CHANNEL_1) != HAL_OK)
  {
    Error_Handler();
  }

}

static void MX_LPTIM4_Init(void)
{

  LPTIM_OC_ConfigTypeDef sConfig1 = {0};

  hlptim4.Instance = LPTIM4;
  hlptim4.Init.Clock.Source = LPTIM_CLOCKSOURCE_APBCLOCK_LPOSC;
  hlptim4.Init.Clock.Prescaler = LPTIM_PRESCALER_DIV1;
  hlptim4.Init.Trigger.Source = LPTIM_TRIGSOURCE_SOFTWARE;
  hlptim4.Init.Period = 65535;
  hlptim4.Init.UpdateMode = LPTIM_UPDATE_IMMEDIATE;
  hlptim4.Init.CounterSource = LPTIM_COUNTERSOURCE_INTERNAL;
  hlptim4.Init.Input1Source = LPTIM_INPUT1SOURCE_GPIO;
  hlptim4.Init.RepetitionCounter = 0;
  if (HAL_LPTIM_Init(&hlptim4) != HAL_OK)
  {
    Error_Handler();
  }
  sConfig1.Pulse = 0;
  sConfig1.OCPolarity = LPTIM_OCPOLARITY_HIGH;
  if (HAL_LPTIM_OC_ConfigChannel(&hlptim4, &sConfig1, LPTIM_CHANNEL_1) != HAL_OK)
  {
    Error_Handler();
  }

}

static void MX_LPUART1_UART_Init(void)
{

  hlpuart1.Instance = LPUART1;
  hlpuart1.Init.BaudRate = 209700;
  hlpuart1.Init.WordLength = UART_WORDLENGTH_8B;
  hlpuart1.Init.StopBits = UART_STOPBITS_1;
  hlpuart1.Init.Parity = UART_PARITY_NONE;
  hlpuart1.Init.Mode = UART_MODE_TX_RX;
  hlpuart1.Init.HwFlowCtl = UART_HWCONTROL_NONE;
  hlpuart1.Init.OneBitSampling = UART_ONE_BIT_SAMPLE_DISABLE;
  hlpuart1.Init.ClockPrescaler = UART_PRESCALER_DIV1;
  hlpuart1.AdvancedInit.AdvFeatureInit = UART_ADVFEATURE_NO_INIT;
  hlpuart1.FifoMode = UART_FIFOMODE_DISABLE;
  if (HAL_UART_Init(&hlpuart1) != HAL_OK)
  {
    Error_Handler();
  }
  if (HAL_UARTEx_SetTxFifoThreshold(&hlpuart1, UART_TXFIFO_THRESHOLD_1_8) != HAL_OK)
  {
    Error_Handler();
  }
  if (HAL_UARTEx_SetRxFifoThreshold(&hlpuart1, UART_RXFIFO_THRESHOLD_1_8) != HAL_OK)
  {
    Error_Handler();
  }
  if (HAL_UARTEx_DisableFifoMode(&hlpuart1) != HAL_OK)
  {
    Error_Handler();
  }
  if (HAL_RS485Ex_Init(&hlpuart1, UART_DE_POLARITY_HIGH, 0, 0) != HAL_OK)
  {
    Error_Handler();
  }

}

static void MX_UART4_Init(void)
{

  huart4.Instance = UART4;
  huart4.Init.BaudRate = 115200;
  huart4.Init.WordLength = UART_WORDLENGTH_8B;
  huart4.Init.StopBits = UART_STOPBITS_1;
  huart4.Init.Parity = UART_PARITY_NONE;
  huart4.Init.Mode = UART_MODE_TX_RX;
  huart4.Init.HwFlowCtl = UART_HWCONTROL_NONE;
  huart4.Init.OverSampling = UART_OVERSAMPLING_16;
  huart4.Init.OneBitSampling = UART_ONE_BIT_SAMPLE_DISABLE;
  huart4.Init.ClockPrescaler = UART_PRESCALER_DIV1;
  huart4.AdvancedInit.AdvFeatureInit = UART_ADVFEATURE_NO_INIT;
  if (HAL_UART_Init(&huart4) != HAL_OK)
  {
    Error_Handler();
  }
  if (HAL_UARTEx_SetTxFifoThreshold(&huart4, UART_TXFIFO_THRESHOLD_1_8) != HAL_OK)
  {
    Error_Handler();
  }
  if (HAL_UARTEx_SetRxFifoThreshold(&huart4, UART_RXFIFO_THRESHOLD_1_8) != HAL_OK)
  {
    Error_Handler();
  }
  if (HAL_UARTEx_DisableFifoMode(&huart4) != HAL_OK)
  {
    Error_Handler();
  }

}

static void MX_UART5_Init(void)
{

  huart5.Instance = UART5;
  huart5.Init.BaudRate = 115200;
  huart5.Init.WordLength = UART_WORDLENGTH_8B;
  huart5.Init.StopBits = UART_STOPBITS_1;
  huart5.Init.Parity = UART_PARITY_NONE;
  huart5.Init.Mode = UART_MODE_TX_RX;
  huart5.Init.HwFlowCtl = UART_HWCONTROL_NONE;
  huart5.Init.OverSampling = UART_OVERSAMPLING_16;
  huart5.Init.OneBitSampling = UART_ONE_BIT_SAMPLE_DISABLE;
  huart5.Init.ClockPrescaler = UART_PRESCALER_DIV1;
  huart5.AdvancedInit.AdvFeatureInit = UART_ADVFEATURE_NO_INIT;
  if (HAL_RS485Ex_Init(&huart5, UART_DE_POLARITY_HIGH, 0, 0) != HAL_OK)
  {
    Error_Handler();
  }
  if (HAL_UARTEx_SetTxFifoThreshold(&huart5, UART_TXFIFO_THRESHOLD_1_8) != HAL_OK)
  {
    Error_Handler();
  }
  if (HAL_UARTEx_SetRxFifoThreshold(&huart5, UART_RXFIFO_THRESHOLD_1_8) != HAL_OK)
  {
    Error_Handler();
  }
  if (HAL_UARTEx_DisableFifoMode(&huart5) != HAL_OK)
  {
    Error_Handler();
  }

}

static void MX_USART1_UART_Init(void)
{

  huart1.Instance = USART1;
  huart1.Init.BaudRate = 115200;
  huart1.Init.WordLength = UART_WORDLENGTH_8B;
  huart1.Init.StopBits = UART_STOPBITS_1;
  huart1.Init.Parity = UART_PARITY_NONE;
  huart1.Init.Mode = UART_MODE_TX_RX;
  huart1.Init.HwFlowCtl = UART_HWCONTROL_NONE;
  huart1.Init.OverSampling = UART_OVERSAMPLING_16;
  huart1.Init.OneBitSampling = UART_ONE_BIT_SAMPLE_DISABLE;
  huart1.Init.ClockPrescaler = UART_PRESCALER_DIV1;
  huart1.AdvancedInit.AdvFeatureInit = UART_ADVFEATURE_NO_INIT;
  if (HAL_UART_Init(&huart1) != HAL_OK)
  {
    Error_Handler();
  }
  if (HAL_UARTEx_SetTxFifoThreshold(&huart1, UART_TXFIFO_THRESHOLD_1_8) != HAL_OK)
  {
    Error_Handler();
  }
  if (HAL_UARTEx_SetRxFifoThreshold(&huart1, UART_RXFIFO_THRESHOLD_1_8) != HAL_OK)
  {
    Error_Handler();
  }
  if (HAL_UARTEx_DisableFifoMode(&huart1) != HAL_OK)
  {
    Error_Handler();
  }

}

static void MX_USART2_UART_Init(void)
{

  huart2.Instance = USART2;
  huart2.Init.BaudRate = 115200;
  huart2.Init.WordLength = UART_WORDLENGTH_8B;
  huart2.Init.StopBits = UART_STOPBITS_1;
  huart2.Init.Parity = UART_PARITY_NONE;
  huart2.Init.Mode = UART_MODE_TX_RX;
  huart2.Init.HwFlowCtl = UART_HWCONTROL_NONE;
  huart2.Init.OverSampling = UART_OVERSAMPLING_16;
  huart2.Init.OneBitSampling = UART_ONE_BIT_SAMPLE_DISABLE;
  huart2.Init.ClockPrescaler = UART_PRESCALER_DIV1;
  huart2.AdvancedInit.AdvFeatureInit = UART_ADVFEATURE_NO_INIT;
  if (HAL_UART_Init(&huart2) != HAL_OK)
  {
    Error_Handler();
  }
  if (HAL_UARTEx_SetTxFifoThreshold(&huart2, UART_TXFIFO_THRESHOLD_1_8) != HAL_OK)
  {
    Error_Handler();
  }
  if (HAL_UARTEx_SetRxFifoThreshold(&huart2, UART_RXFIFO_THRESHOLD_1_8) != HAL_OK)
  {
    Error_Handler();
  }
  if (HAL_UARTEx_DisableFifoMode(&huart2) != HAL_OK)
  {
    Error_Handler();
  }

}

static void MX_USART3_UART_Init(void)
{

  huart3.Instance = USART3;
  huart3.Init.BaudRate = 115200;
  huart3.Init.WordLength = UART_WORDLENGTH_8B;
  huart3.Init.StopBits = UART_STOPBITS_1;
  huart3.Init.Parity = UART_PARITY_NONE;
  huart3.Init.Mode = UART_MODE_TX_RX;
  huart3.Init.HwFlowCtl = UART_HWCONTROL_NONE;
  huart3.Init.OverSampling = UART_OVERSAMPLING_16;
  huart3.Init.OneBitSampling = UART_ONE_BIT_SAMPLE_DISABLE;
  huart3.Init.ClockPrescaler = UART_PRESCALER_DIV1;
  huart3.AdvancedInit.AdvFeatureInit = UART_ADVFEATURE_NO_INIT;
  if (HAL_UART_Init(&huart3) != HAL_OK)
  {
    Error_Handler();
  }
  if (HAL_UARTEx_SetTxFifoThreshold(&huart3, UART_TXFIFO_THRESHOLD_1_8) != HAL_OK)
  {
    Error_Handler();
  }
  if (HAL_UARTEx_SetRxFifoThreshold(&huart3, UART_RXFIFO_THRESHOLD_1_8) != HAL_OK)
  {
    Error_Handler();
  }
  if (HAL_UARTEx_DisableFifoMode(&huart3) != HAL_OK)
  {
    Error_Handler();
  }

}

static void MX_OCTOSPI1_Init(void)
{

  /* OCTOSPI1 parameter configuration*/
  hxspi1.Instance = OCTOSPI1;
  hxspi1.Init.FifoThresholdByte = 1;
  hxspi1.Init.MemoryMode = HAL_XSPI_SINGLE_MEM;
  hxspi1.Init.MemoryType = HAL_XSPI_MEMTYPE_MICRON;
  hxspi1.Init.MemorySize = HAL_XSPI_SIZE_32MB;
  hxspi1.Init.ChipSelectHighTimeCycle = 1;
  hxspi1.Init.FreeRunningClock = HAL_XSPI_FREERUNCLK_DISABLE;
  hxspi1.Init.ClockMode = HAL_XSPI_CLOCK_MODE_3;
  hxspi1.Init.WrapSize = HAL_XSPI_WRAP_NOT_SUPPORTED;
  hxspi1.Init.ClockPrescaler = 0;
  hxspi1.Init.SampleShifting = HAL_XSPI_SAMPLE_SHIFT_NONE;
  hxspi1.Init.DelayHoldQuarterCycle = HAL_XSPI_DHQC_DISABLE;
  hxspi1.Init.ChipSelectBoundary = HAL_XSPI_BONDARYOF_NONE;
  hxspi1.Init.DelayBlockBypass = HAL_XSPI_DELAY_BLOCK_BYPASS;
  hxspi1.Init.Refresh = 0;
  if (HAL_XSPI_Init(&hxspi1) != HAL_OK)
  {
    Error_Handler();
  }

}

static void MX_RTC_Init(void)
{

  RTC_PrivilegeStateTypeDef privilegeState = {0};

  /** Initialize RTC Only
  */
  hrtc.Instance = RTC;
  hrtc.Init.HourFormat = RTC_HOURFORMAT_24;
  hrtc.Init.AsynchPrediv = 127;
  hrtc.Init.SynchPrediv = 255;
  hrtc.Init.OutPut = RTC_OUTPUT_DISABLE;
  hrtc.Init.OutPutRemap = RTC_OUTPUT_REMAP_NONE;
  hrtc.Init.OutPutPolarity = RTC_OUTPUT_POLARITY_HIGH;
  hrtc.Init.OutPutType = RTC_OUTPUT_TYPE_OPENDRAIN;
  hrtc.Init.OutPutPullUp = RTC_OUTPUT_PULLUP_NONE;
  hrtc.Init.BinMode = RTC_BINARY_NONE;
  if (HAL_RTC_Init(&hrtc) != HAL_OK)
  {
    Error_Handler();
  }
  privilegeState.rtcPrivilegeFull = RTC_PRIVILEGE_FULL_NO;
  privilegeState.backupRegisterPrivZone = RTC_PRIVILEGE_BKUP_ZONE_NONE;
  privilegeState.backupRegisterStartZone2 = RTC_BKP_DR0;
  privilegeState.backupRegisterStartZone3 = RTC_BKP_DR0;
  if (HAL_RTCEx_PrivilegeModeSet(&hrtc, &privilegeState) != HAL_OK)
  {
    Error_Handler();
  }

}

static void MX_SPI1_Init(void)
{

  SPI_AutonomousModeConfTypeDef HAL_SPI_AutonomousMode_Cfg_Struct = {0};

  /* SPI1 parameter configuration*/
  hspi1.Instance = SPI1;
  hspi1.Init.Mode = SPI_MODE_MASTER;
  hspi1.Init.Direction = SPI_DIRECTION_1LINE;
  hspi1.Init.DataSize = SPI_DATASIZE_8BIT;
  hspi1.Init.CLKPolarity = SPI_POLARITY_LOW;
  hspi1.Init.CLKPhase = SPI_PHASE_1EDGE;
  hspi1.Init.NSS = SPI_NSS_HARD_OUTPUT;
  hspi1.Init.BaudRatePrescaler = SPI_BAUDRATEPRESCALER_2;
  hspi1.Init.FirstBit = SPI_FIRSTBIT_MSB;
  hspi1.Init.TIMode = SPI_TIMODE_DISABLE;
  hspi1.Init.CRCCalculation = SPI_CRCCALCULATION_DISABLE;
  hspi1.Init.CRCPolynomial = 0x7;
  hspi1.Init.NSSPMode = SPI_NSS_PULSE_ENABLE;
  hspi1.Init.NSSPolarity = SPI_NSS_POLARITY_LOW;
  hspi1.Init.FifoThreshold = SPI_FIFO_THRESHOLD_01DATA;
  hspi1.Init.MasterSSIdleness = SPI_MASTER_SS_IDLENESS_00CYCLE;
  hspi1.Init.MasterInterDataIdleness = SPI_MASTER_INTERDATA_IDLENESS_00CYCLE;
  hspi1.Init.MasterReceiverAutoSusp = SPI_MASTER_RX_AUTOSUSP_DISABLE;
  hspi1.Init.MasterKeepIOState = SPI_MASTER_KEEP_IO_STATE_DISABLE;
  hspi1.Init.IOSwap = SPI_IO_SWAP_DISABLE;
  hspi1.Init.ReadyMasterManagement = SPI_RDY_MASTER_MANAGEMENT_INTERNALLY;
  hspi1.Init.ReadyPolarity = SPI_RDY_POLARITY_HIGH;
  if (HAL_SPI_Init(&hspi1) != HAL_OK)
  {
    Error_Handler();
  }
  HAL_SPI_AutonomousMode_Cfg_Struct.TriggerState = SPI_AUTO_MODE_DISABLE;
  HAL_SPI_AutonomousMode_Cfg_Struct.TriggerSelection = SPI_GRP1_GPDMA_CH0_TCF_TRG;
  HAL_SPI_AutonomousMode_Cfg_Struct.TriggerPolarity = SPI_TRIG_POLARITY_RISING;
  if (HAL_SPIEx_SetConfigAutonomousMode(&hspi1, &HAL_SPI_AutonomousMode_Cfg_Struct) != HAL_OK)
  {
    Error_Handler();
  }

}

static void MX_SPI2_Init(void)
{

  SPI_AutonomousModeConfTypeDef HAL_SPI_AutonomousMode_Cfg_Struct = {0};

  /* SPI2 parameter configuration*/
  hspi2.Instance = SPI2;
  hspi2.Init.Mode = SPI_MODE_MASTER;
  hspi2.Init.Direction = SPI_DIRECTION_2LINES;
  hspi2.Init.DataSize = SPI_DATASIZE_4BIT;
  hspi2.Init.CLKPolarity = SPI_POLARITY_LOW;
  hspi2.Init.CLKPhase = SPI_PHASE_1EDGE;
  hspi2.Init.NSS = SPI_NSS_HARD_OUTPUT;
  hspi2.Init.BaudRatePrescaler = SPI_BAUDRATEPRESCALER_2;
  hspi2.Init.FirstBit = SPI_FIRSTBIT_MSB;
  hspi2.Init.TIMode = SPI_TIMODE_DISABLE;
  hspi2.Init.CRCCalculation = SPI_CRCCALCULATION_DISABLE;
  hspi2.Init.CRCPolynomial = 0x7;
  hspi2.Init.NSSPMode = SPI_NSS_PULSE_ENABLE;
  hspi2.Init.NSSPolarity = SPI_NSS_POLARITY_LOW;
  hspi2.Init.FifoThreshold = SPI_FIFO_THRESHOLD_01DATA;
  hspi2.Init.MasterSSIdleness = SPI_MASTER_SS_IDLENESS_00CYCLE;
  hspi2.Init.MasterInterDataIdleness = SPI_MASTER_INTERDATA_IDLENESS_00CYCLE;
  hspi2.Init.MasterReceiverAutoSusp = SPI_MASTER_RX_AUTOSUSP_DISABLE;
  hspi2.Init.MasterKeepIOState = SPI_MASTER_KEEP_IO_STATE_DISABLE;
  hspi2.Init.IOSwap = SPI_IO_SWAP_DISABLE;
  hspi2.Init.ReadyMasterManagement = SPI_RDY_MASTER_MANAGEMENT_INTERNALLY;
  hspi2.Init.ReadyPolarity = SPI_RDY_POLARITY_HIGH;
  if (HAL_SPI_Init(&hspi2) != HAL_OK)
  {
    Error_Handler();
  }
  HAL_SPI_AutonomousMode_Cfg_Struct.TriggerState = SPI_AUTO_MODE_DISABLE;
  HAL_SPI_AutonomousMode_Cfg_Struct.TriggerSelection = SPI_GRP1_GPDMA_CH0_TCF_TRG;
  HAL_SPI_AutonomousMode_Cfg_Struct.TriggerPolarity = SPI_TRIG_POLARITY_RISING;
  if (HAL_SPIEx_SetConfigAutonomousMode(&hspi2, &HAL_SPI_AutonomousMode_Cfg_Struct) != HAL_OK)
  {
    Error_Handler();
  }

}

static void MX_SPI3_Init(void)
{

  SPI_AutonomousModeConfTypeDef HAL_SPI_AutonomousMode_Cfg_Struct = {0};

  /* SPI3 parameter configuration*/
  hspi3.Instance = SPI3;
  hspi3.Init.Mode = SPI_MODE_MASTER;
  hspi3.Init.Direction = SPI_DIRECTION_2LINES;
  hspi3.Init.DataSize = SPI_DATASIZE_8BIT;
  hspi3.Init.CLKPolarity = SPI_POLARITY_LOW;
  hspi3.Init.CLKPhase = SPI_PHASE_1EDGE;
  hspi3.Init.NSS = SPI_NSS_SOFT;
  hspi3.Init.BaudRatePrescaler = SPI_BAUDRATEPRESCALER_2;
  hspi3.Init.FirstBit = SPI_FIRSTBIT_MSB;
  hspi3.Init.TIMode = SPI_TIMODE_DISABLE;
  hspi3.Init.CRCCalculation = SPI_CRCCALCULATION_DISABLE;
  hspi3.Init.CRCPolynomial = 0x7;
  hspi3.Init.NSSPMode = SPI_NSS_PULSE_ENABLE;
  hspi3.Init.NSSPolarity = SPI_NSS_POLARITY_LOW;
  hspi3.Init.FifoThreshold = SPI_FIFO_THRESHOLD_01DATA;
  hspi3.Init.MasterSSIdleness = SPI_MASTER_SS_IDLENESS_00CYCLE;
  hspi3.Init.MasterInterDataIdleness = SPI_MASTER_INTERDATA_IDLENESS_00CYCLE;
  hspi3.Init.MasterReceiverAutoSusp = SPI_MASTER_RX_AUTOSUSP_DISABLE;
  hspi3.Init.MasterKeepIOState = SPI_MASTER_KEEP_IO_STATE_DISABLE;
  hspi3.Init.IOSwap = SPI_IO_SWAP_DISABLE;
  hspi3.Init.ReadyMasterManagement = SPI_RDY_MASTER_MANAGEMENT_INTERNALLY;
  hspi3.Init.ReadyPolarity = SPI_RDY_POLARITY_HIGH;
  if (HAL_SPI_Init(&hspi3) != HAL_OK)
  {
    Error_Handler();
  }
  HAL_SPI_AutonomousMode_Cfg_Struct.TriggerState = SPI_AUTO_MODE_DISABLE;
  HAL_SPI_AutonomousMode_Cfg_Struct.TriggerSelection = SPI_GRP2_GPDMA_CH0_TCF_TRG;
  HAL_SPI_AutonomousMode_Cfg_Struct.TriggerPolarity = SPI_TRIG_POLARITY_RISING;
  if (HAL_SPIEx_SetConfigAutonomousMode(&hspi3, &HAL_SPI_AutonomousMode_Cfg_Struct) != HAL_OK)
  {
    Error_Handler();
  }

}

static void MX_SPI4_Init(void)
{

  SPI_AutonomousModeConfTypeDef HAL_SPI_AutonomousMode_Cfg_Struct = {0};

  /* SPI4 parameter configuration*/
  hspi4.Instance = SPI4;
  hspi4.Init.Mode = SPI_MODE_MASTER;
  hspi4.Init.Direction = SPI_DIRECTION_2LINES;
  hspi4.Init.DataSize = SPI_DATASIZE_8BIT;
  hspi4.Init.CLKPolarity = SPI_POLARITY_LOW;
  hspi4.Init.CLKPhase = SPI_PHASE_1EDGE;
  hspi4.Init.NSS = SPI_NSS_SOFT;
  hspi4.Init.BaudRatePrescaler = SPI_BAUDRATEPRESCALER_2;
  hspi4.Init.FirstBit = SPI_FIRSTBIT_MSB;
  hspi4.Init.TIMode = SPI_TIMODE_DISABLE;
  hspi4.Init.CRCCalculation = SPI_CRCCALCULATION_DISABLE;
  hspi4.Init.CRCPolynomial = 0x7;
  hspi4.Init.NSSPMode = SPI_NSS_PULSE_ENABLE;
  hspi4.Init.NSSPolarity = SPI_NSS_POLARITY_LOW;
  hspi4.Init.FifoThreshold = SPI_FIFO_THRESHOLD_01DATA;
  hspi4.Init.MasterSSIdleness = SPI_MASTER_SS_IDLENESS_00CYCLE;
  hspi4.Init.MasterInterDataIdleness = SPI_MASTER_INTERDATA_IDLENESS_00CYCLE;
  hspi4.Init.MasterReceiverAutoSusp = SPI_MASTER_RX_AUTOSUSP_DISABLE;
  hspi4.Init.MasterKeepIOState = SPI_MASTER_KEEP_IO_STATE_DISABLE;
  hspi4.Init.IOSwap = SPI_IO_SWAP_DISABLE;
  hspi4.Init.ReadyMasterManagement = SPI_RDY_MASTER_MANAGEMENT_INTERNALLY;
  hspi4.Init.ReadyPolarity = SPI_RDY_POLARITY_HIGH;
  if (HAL_SPI_Init(&hspi4) != HAL_OK)
  {
    Error_Handler();
  }
  HAL_SPI_AutonomousMode_Cfg_Struct.TriggerState = SPI_AUTO_MODE_DISABLE;
  HAL_SPI_AutonomousMode_Cfg_Struct.TriggerSelection = SPI_GRP1_GPDMA_CH0_TCF_TRG;
  HAL_SPI_AutonomousMode_Cfg_Struct.TriggerPolarity = SPI_TRIG_POLARITY_RISING;
  if (HAL_SPIEx_SetConfigAutonomousMode(&hspi4, &HAL_SPI_AutonomousMode_Cfg_Struct) != HAL_OK)
  {
    Error_Handler();
  }

}

static void MX_TIM1_Init(void)
{

  TIM_ClockConfigTypeDef sClockSourceConfig = {0};
  TIM_MasterConfigTypeDef sMasterConfig = {0};
  TIM_OC_InitTypeDef sConfigOC = {0};
  TIM_BreakDeadTimeConfigTypeDef sBreakDeadTimeConfig = {0};

  htim1.Instance = TIM1;
  htim1.Init.Prescaler = 23;
  htim1.Init.CounterMode = TIM_COUNTERMODE_CENTERALIGNED3;
  htim1.Init.Period = 500;
  htim1.Init.ClockDivision = TIM_CLOCKDIVISION_DIV1;
  htim1.Init.RepetitionCounter = 1999;
  htim1.Init.AutoReloadPreload = TIM_AUTORELOAD_PRELOAD_DISABLE;
  if (HAL_TIM_Base_Init(&htim1) != HAL_OK)
  {
    Error_Handler();
  }
  sClockSourceConfig.ClockSource = TIM_CLOCKSOURCE_INTERNAL;
  if (HAL_TIM_ConfigClockSource(&htim1, &sClockSourceConfig) != HAL_OK)
  {
    Error_Handler();
  }
  if (HAL_TIM_PWM_Init(&htim1) != HAL_OK)
  {
    Error_Handler();
  }
  if (HAL_TIM_OC_Init(&htim1) != HAL_OK)
  {
    Error_Handler();
  }
  sMasterConfig.MasterOutputTrigger = TIM_TRGO_RESET;
  sMasterConfig.MasterOutputTrigger2 = TIM_TRGO2_RESET;
  sMasterConfig.MasterSlaveMode = TIM_MASTERSLAVEMODE_DISABLE;
  if (HAL_TIMEx_MasterConfigSynchronization(&htim1, &sMasterConfig) != HAL_OK)
  {
    Error_Handler();
  }
  sConfigOC.OCMode = TIM_OCMODE_ASSYMETRIC_PWM1;
  sConfigOC.Pulse = 125;
  sConfigOC.OCPolarity = TIM_OCPOLARITY_HIGH;
  sConfigOC.OCNPolarity = TIM_OCNPOLARITY_HIGH;
  sConfigOC.OCFastMode = TIM_OCFAST_DISABLE;
  sConfigOC.OCIdleState = TIM_OCIDLESTATE_RESET;
  sConfigOC.OCNIdleState = TIM_OCNIDLESTATE_RESET;
  if (HAL_TIM_PWM_ConfigChannel(&htim1, &sConfigOC, TIM_CHANNEL_1) != HAL_OK)
  {
    Error_Handler();
  }
  __HAL_TIM_DISABLE_OCxPRELOAD(&htim1, TIM_CHANNEL_1);
  sConfigOC.OCMode = TIM_OCMODE_TIMING;
  sConfigOC.Pulse = 375;
  if (HAL_TIM_OC_ConfigChannel(&htim1, &sConfigOC, TIM_CHANNEL_2) != HAL_OK)
  {
    Error_Handler();
  }
  sConfigOC.OCMode = TIM_OCMODE_ASSYMETRIC_PWM2;
  if (HAL_TIM_PWM_ConfigChannel(&htim1, &sConfigOC, TIM_CHANNEL_3) != HAL_OK)
  {
    Error_Handler();
  }
  __HAL_TIM_DISABLE_OCxPRELOAD(&htim1, TIM_CHANNEL_3);
  sConfigOC.OCMode = TIM_OCMODE_TIMING;
  sConfigOC.Pulse = 25;
  if (HAL_TIM_OC_ConfigChannel(&htim1, &sConfigOC, TIM_CHANNEL_4) != HAL_OK)
  {
    Error_Handler();
  }
  sBreakDeadTimeConfig.OffStateRunMode = TIM_OSSR_DISABLE;
  sBreakDeadTimeConfig.OffStateIDLEMode = TIM_OSSI_DISABLE;
  sBreakDeadTimeConfig.LockLevel = TIM_LOCKLEVEL_OFF;
  sBreakDeadTimeConfig.DeadTime = 0;
  sBreakDeadTimeConfig.BreakState = TIM_BREAK_DISABLE;
  sBreakDeadTimeConfig.BreakPolarity = TIM_BREAKPOLARITY_HIGH;
  sBreakDeadTimeConfig.BreakFilter = 0;
  sBreakDeadTimeConfig.BreakAFMode = TIM_BREAK_AFMODE_INPUT;
  sBreakDeadTimeConfig.Break2State = TIM_BREAK2_DISABLE;
  sBreakDeadTimeConfig.Break2Polarity = TIM_BREAK2POLARITY_HIGH;
  sBreakDeadTimeConfig.Break2Filter = 0;
  sBreakDeadTimeConfig.Break2AFMode = TIM_BREAK_AFMODE_INPUT;
  sBreakDeadTimeConfig.AutomaticOutput = TIM_AUTOMATICOUTPUT_DISABLE;
  if (HAL_TIMEx_ConfigBreakDeadTime(&htim1, &sBreakDeadTimeConfig) != HAL_OK)
  {
    Error_Handler();
  }
  HAL_TIM_MspPostInit(&htim1);

}

static void MX_TIM2_Init(void)
{

  TIM_Encoder_InitTypeDef sConfig = {0};
  TIM_MasterConfigTypeDef sMasterConfig = {0};

  htim2.Instance = TIM2;
  htim2.Init.Prescaler = 0;
  htim2.Init.CounterMode = TIM_COUNTERMODE_UP;
  htim2.Init.Period = 4294967295;
  htim2.Init.ClockDivision = TIM_CLOCKDIVISION_DIV1;
  htim2.Init.AutoReloadPreload = TIM_AUTORELOAD_PRELOAD_DISABLE;
  sConfig.EncoderMode = TIM_ENCODERMODE_TI1;
  sConfig.IC1Polarity = TIM_ICPOLARITY_RISING;
  sConfig.IC1Selection = TIM_ICSELECTION_DIRECTTI;
  sConfig.IC1Prescaler = TIM_ICPSC_DIV1;
  sConfig.IC1Filter = 0;
  sConfig.IC2Polarity = TIM_ICPOLARITY_RISING;
  sConfig.IC2Selection = TIM_ICSELECTION_DIRECTTI;
  sConfig.IC2Prescaler = TIM_ICPSC_DIV1;
  sConfig.IC2Filter = 0;
  if (HAL_TIM_Encoder_Init(&htim2, &sConfig) != HAL_OK)
  {
    Error_Handler();
  }
  sMasterConfig.MasterOutputTrigger = TIM_TRGO_RESET;
  sMasterConfig.MasterSlaveMode = TIM_MASTERSLAVEMODE_DISABLE;
  if (HAL_TIMEx_MasterConfigSynchronization(&htim2, &sMasterConfig) != HAL_OK)
  {
    Error_Handler();
  }

}

static void MX_TIM3_Init(void)
{

  TIM_Encoder_InitTypeDef sConfig = {0};
  TIM_MasterConfigTypeDef sMasterConfig = {0};

  htim3.Instance = TIM3;
  htim3.Init.Prescaler = 0;
  htim3.Init.CounterMode = TIM_COUNTERMODE_UP;
  htim3.Init.Period = 4294967295;
  htim3.Init.ClockDivision = TIM_CLOCKDIVISION_DIV1;
  htim3.Init.AutoReloadPreload = TIM_AUTORELOAD_PRELOAD_DISABLE;
  sConfig.EncoderMode = TIM_ENCODERMODE_TI1;
  sConfig.IC1Polarity = TIM_ICPOLARITY_RISING;
  sConfig.IC1Selection = TIM_ICSELECTION_DIRECTTI;
  sConfig.IC1Prescaler = TIM_ICPSC_DIV1;
  sConfig.IC1Filter = 0;
  sConfig.IC2Polarity = TIM_ICPOLARITY_RISING;
  sConfig.IC2Selection = TIM_ICSELECTION_DIRECTTI;
  sConfig.IC2Prescaler = TIM_ICPSC_DIV1;
  sConfig.IC2Filter = 0;
  if (HAL_TIM_Encoder_Init(&htim3, &sConfig) != HAL_OK)
  {
    Error_Handler();
  }
  sMasterConfig.MasterOutputTrigger = TIM_TRGO_RESET;
  sMasterConfig.MasterSlaveMode = TIM_MASTERSLAVEMODE_DISABLE;
  if (HAL_TIMEx_MasterConfigSynchronization(&htim3, &sMasterConfig) != HAL_OK)
  {
    Error_Handler();
  }

}

static void MX_TIM4_Init(void)
{

  TIM_MasterConfigTypeDef sMasterConfig = {0};
  TIM_OC_InitTypeDef sConfigOC = {0};

  htim4.Instance = TIM4;
  htim4.Init.Prescaler = 0;
  htim4.Init.CounterMode = TIM_COUNTERMODE_UP;
  htim4.Init.Period = 4294967295;
  htim4.Init.ClockDivision = TIM_CLOCKDIVISION_DIV1;
  htim4.Init.AutoReloadPreload = TIM_AUTORELOAD_PRELOAD_DISABLE;
  if (HAL_TIM_PWM_Init(&htim4) != HAL_OK)
  {
    Error_Handler();
  }
  sMasterConfig.MasterOutputTrigger = TIM_TRGO_RESET;
  sMasterConfig.MasterSlaveMode = TIM_MASTERSLAVEMODE_DISABLE;
  if (HAL_TIMEx_MasterConfigSynchronization(&htim4, &sMasterConfig) != HAL_OK)
  {
    Error_Handler();
  }
  sConfigOC.OCMode = TIM_OCMODE_PWM1;
  sConfigOC.Pulse = 0;
  sConfigOC.OCPolarity = TIM_OCPOLARITY_HIGH;
  sConfigOC.OCFastMode = TIM_OCFAST_DISABLE;
  if (HAL_TIM_PWM_ConfigChannel(&htim4, &sConfigOC, TIM_CHANNEL_2) != HAL_OK)
  {
    Error_Handler();
  }
  HAL_TIM_MspPostInit(&htim4);

}

static void MX_TIM8_Init(void)
{

  TIM_MasterConfigTypeDef sMasterConfig = {0};
  TIM_OC_InitTypeDef sConfigOC = {0};
  TIM_BreakDeadTimeConfigTypeDef sBreakDeadTimeConfig = {0};

  htim8.Instance = TIM8;
  htim8.Init.Prescaler = 0;
  htim8.Init.CounterMode = TIM_COUNTERMODE_UP;
  htim8.Init.Period = 65535;
  htim8.Init.ClockDivision = TIM_CLOCKDIVISION_DIV1;
  htim8.Init.RepetitionCounter = 0;
  htim8.Init.AutoReloadPreload = TIM_AUTORELOAD_PRELOAD_DISABLE;
  if (HAL_TIM_PWM_Init(&htim8) != HAL_OK)
  {
    Error_Handler();
  }
  sMasterConfig.MasterOutputTrigger = TIM_TRGO_RESET;
  sMasterConfig.MasterOutputTrigger2 = TIM_TRGO2_RESET;
  sMasterConfig.MasterSlaveMode = TIM_MASTERSLAVEMODE_DISABLE;
  if (HAL_TIMEx_MasterConfigSynchronization(&htim8, &sMasterConfig) != HAL_OK)
  {
    Error_Handler();
  }
  sConfigOC.OCMode = TIM_OCMODE_PWM1;
  sConfigOC.Pulse = 0;
  sConfigOC.OCPolarity = TIM_OCPOLARITY_HIGH;
  sConfigOC.OCNPolarity = TIM_OCNPOLARITY_HIGH;
  sConfigOC.OCFastMode = TIM_OCFAST_DISABLE;
  sConfigOC.OCIdleState = TIM_OCIDLESTATE_RESET;
  sConfigOC.OCNIdleState = TIM_OCNIDLESTATE_RESET;
  if (HAL_TIM_PWM_ConfigChannel(&htim8, &sConfigOC, TIM_CHANNEL_1) != HAL_OK)
  {
    Error_Handler();
  }
  if (HAL_TIM_PWM_ConfigChannel(&htim8, &sConfigOC, TIM_CHANNEL_2) != HAL_OK)
  {
    Error_Handler();
  }
  sBreakDeadTimeConfig.OffStateRunMode = TIM_OSSR_DISABLE;
  sBreakDeadTimeConfig.OffStateIDLEMode = TIM_OSSI_DISABLE;
  sBreakDeadTimeConfig.LockLevel = TIM_LOCKLEVEL_OFF;
  sBreakDeadTimeConfig.DeadTime = 0;
  sBreakDeadTimeConfig.BreakState = TIM_BREAK_DISABLE;
  sBreakDeadTimeConfig.BreakPolarity = TIM_BREAKPOLARITY_HIGH;
  sBreakDeadTimeConfig.BreakFilter = 0;
  sBreakDeadTimeConfig.BreakAFMode = TIM_BREAK_AFMODE_INPUT;
  sBreakDeadTimeConfig.Break2State = TIM_BREAK2_DISABLE;
  sBreakDeadTimeConfig.Break2Polarity = TIM_BREAK2POLARITY_HIGH;
  sBreakDeadTimeConfig.Break2Filter = 0;
  sBreakDeadTimeConfig.Break2AFMode = TIM_BREAK_AFMODE_INPUT;
  sBreakDeadTimeConfig.AutomaticOutput = TIM_AUTOMATICOUTPUT_DISABLE;
  if (HAL_TIMEx_ConfigBreakDeadTime(&htim8, &sBreakDeadTimeConfig) != HAL_OK)
  {
    Error_Handler();
  }
  HAL_TIM_MspPostInit(&htim8);

}

static void MX_GPIO_Init(void)
{
  GPIO_InitTypeDef GPIO_InitStruct = {0};

  /* GPIO Ports Clock Enable */
  __HAL_RCC_GPIOE_CLK_ENABLE();
  __HAL_RCC_GPIOC_CLK_ENABLE();
  __HAL_RCC_GPIOF_CLK_ENABLE();
  __HAL_RCC_GPIOA_CLK_ENABLE();
  __HAL_RCC_GPIOB_CLK_ENABLE();
  __HAL_RCC_GPIOD_CLK_ENABLE();
  __HAL_RCC_GPIOG_CLK_ENABLE();

  /*Configure GPIO pins : USM_COM_IRQ_EXTI13_Pin DIGITAL_INPUT2_IRQ_EXTI7_Pin OPTICAL_HEAD_IR_DETECT_IRQ_EXTI9_Pin */
  GPIO_InitStruct.Pin = USM_COM_IRQ_EXTI13_Pin|DIGITAL_INPUT2_IRQ_EXTI7_Pin|OPTICAL_HEAD_IR_DETECT_IRQ_EXTI9_Pin;
  GPIO_InitStruct.Mode = GPIO_MODE_IT_RISING;
  GPIO_InitStruct.Pull = GPIO_NOPULL;
  HAL_GPIO_Init(GPIOC, &GPIO_InitStruct);

  /*Configure GPIO pin : EXTERNAL_RTC_ETXI2_Pin */
  GPIO_InitStruct.Pin = EXTERNAL_RTC_ETXI2_Pin;
  GPIO_InitStruct.Mode = GPIO_MODE_IT_RISING;
  GPIO_InitStruct.Pull = GPIO_NOPULL;
  HAL_GPIO_Init(EXTERNAL_RTC_ETXI2_GPIO_Port, &GPIO_InitStruct);

  /*Configure GPIO pins : KEY_DOWN_BUTTON_EXTI6_Pin DIGITAL_INPUT4_IRQ_EXTI11_Pin DIGITAL_INPUT3_IRQ_EXTI12_Pin */
  GPIO_InitStruct.Pin = KEY_DOWN_BUTTON_EXTI6_Pin|DIGITAL_INPUT4_IRQ_EXTI11_Pin|DIGITAL_INPUT3_IRQ_EXTI12_Pin;
  GPIO_InitStruct.Mode = GPIO_MODE_IT_RISING;
  GPIO_InitStruct.Pull = GPIO_NOPULL;
  HAL_GPIO_Init(GPIOA, &GPIO_InitStruct);

  /*Configure GPIO pins : DIGITAL_INPUT1_IRQ_EXTI10_Pin KEY_LEFT_BUTTON_EXTI1_Pin KEY_UP_BUTTON_EXT14_Pin */
  GPIO_InitStruct.Pin = DIGITAL_INPUT1_IRQ_EXTI10_Pin|KEY_LEFT_BUTTON_EXTI1_Pin|KEY_UP_BUTTON_EXT14_Pin;
  GPIO_InitStruct.Mode = GPIO_MODE_IT_RISING;
  GPIO_InitStruct.Pull = GPIO_NOPULL;
  HAL_GPIO_Init(GPIOD, &GPIO_InitStruct);

  /*Configure GPIO pins : KEY_ESCAPE_BUTTON_IRQ_EXTI3_Pin BATTERY_FUEL_GUAGE_IRQ_ETXI15_Pin KEY_ENTER_BUTTON_IRQ_EXTI8_Pin */
  GPIO_InitStruct.Pin = KEY_ESCAPE_BUTTON_IRQ_EXTI3_Pin|BATTERY_FUEL_GUAGE_IRQ_ETXI15_Pin|KEY_ENTER_BUTTON_IRQ_EXTI8_Pin;
  GPIO_InitStruct.Mode = GPIO_MODE_IT_RISING;
  GPIO_InitStruct.Pull = GPIO_NOPULL;
  HAL_GPIO_Init(GPIOG, &GPIO_InitStruct);

  /*Configure GPIO pin : KEY_RIGHT_BUTTON_EXTI0_Pin */
  GPIO_InitStruct.Pin = KEY_RIGHT_BUTTON_EXTI0_Pin;
  GPIO_InitStruct.Mode = GPIO_MODE_IT_RISING;
  GPIO_InitStruct.Pull = GPIO_NOPULL;
  HAL_GPIO_Init(KEY_RIGHT_BUTTON_EXTI0_GPIO_Port, &GPIO_InitStruct);

}

void Error_Handler(void)
{
  __disable_irq();
  while (1)
  {
  }
}
